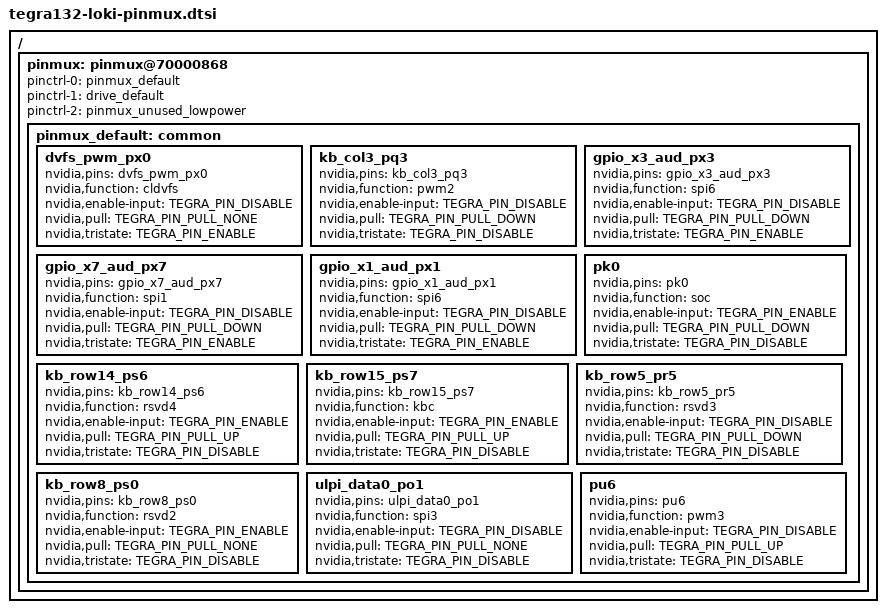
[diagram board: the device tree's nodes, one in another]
#include <dt-bindings/pinctrl/pinctrl-tegra.h>
#include <tegra124-platforms/tegra124-loki-pinmux.dtsi>

/ {
	pinmux: pinmux@70000868 {
		pinctrl-names = "default", "drive", "unused";
		pinctrl-0 = <&pinmux_default>;
		pinctrl-1 = <&drive_default>;
		pinctrl-2 = <&pinmux_unused_lowpower>;

		pinmux_default: common {
			dvfs_pwm_px0 {
				nvidia,pins = "dvfs_pwm_px0";
				nvidia,function = "cldvfs";
				nvidia,enable-input = <TEGRA_PIN_DISABLE>;
				nvidia,pull = <TEGRA_PIN_PULL_NONE>;
				nvidia,tristate = <TEGRA_PIN_ENABLE>;
			};

			kb_col3_pq3 {
				nvidia,pins = "kb_col3_pq3";
				nvidia,function = "pwm2";
				nvidia,enable-input = <TEGRA_PIN_DISABLE>;
				nvidia,pull = <TEGRA_PIN_PULL_DOWN>;
				nvidia,tristate = <TEGRA_PIN_DISABLE>;
			};

			gpio_x3_aud_px3 {
				nvidia,pins = "gpio_x3_aud_px3";
				nvidia,function = "spi6";
				nvidia,enable-input = <TEGRA_PIN_DISABLE>;
				nvidia,pull = <TEGRA_PIN_PULL_DOWN>;
				nvidia,tristate = <TEGRA_PIN_ENABLE>;
			};

			gpio_x7_aud_px7 {
				nvidia,pins = "gpio_x7_aud_px7";
				nvidia,function = "spi1";
				nvidia,enable-input = <TEGRA_PIN_DISABLE>;
				nvidia,pull = <TEGRA_PIN_PULL_DOWN>;
				nvidia,tristate = <TEGRA_PIN_ENABLE>;
			};

			gpio_x1_aud_px1 {
				nvidia,pins = "gpio_x1_aud_px1";
				nvidia,function = "spi6";
				nvidia,enable-input = <TEGRA_PIN_DISABLE>;
				nvidia,pull = <TEGRA_PIN_PULL_DOWN>;
				nvidia,tristate = <TEGRA_PIN_ENABLE>;
			};

			pk0 {
				nvidia,pins = "pk0";
				nvidia,function = "soc";
				nvidia,enable-input = <TEGRA_PIN_ENABLE>;
				nvidia,pull = <TEGRA_PIN_PULL_DOWN>;
				nvidia,tristate = <TEGRA_PIN_DISABLE>;
			};

			kb_row14_ps6 {
				nvidia,pins = "kb_row14_ps6";
				nvidia,function = "rsvd4";
				nvidia,enable-input = <TEGRA_PIN_ENABLE>;
				nvidia,pull = <TEGRA_PIN_PULL_UP>;
				nvidia,tristate = <TEGRA_PIN_DISABLE>;
			};

			kb_row15_ps7 {
				nvidia,pins = "kb_row15_ps7";
				nvidia,function = "kbc";
				nvidia,enable-input = <TEGRA_PIN_ENABLE>;
				nvidia,pull = <TEGRA_PIN_PULL_UP>;
				nvidia,tristate = <TEGRA_PIN_DISABLE>;
			};

			kb_row5_pr5 {
				nvidia,pins = "kb_row5_pr5";
				nvidia,function = "rsvd3";
				nvidia,enable-input = <TEGRA_PIN_DISABLE>;
				nvidia,pull = <TEGRA_PIN_PULL_DOWN>;
				nvidia,tristate = <TEGRA_PIN_DISABLE>;
			};

			kb_row8_ps0 {
				nvidia,pins = "kb_row8_ps0";
				nvidia,function = "rsvd2";
				nvidia,enable-input = <TEGRA_PIN_ENABLE>;
				nvidia,pull = <TEGRA_PIN_PULL_NONE>;
				nvidia,tristate = <TEGRA_PIN_DISABLE>;
			};

			ulpi_data0_po1 {
				nvidia,pins = "ulpi_data0_po1";
				nvidia,function = "spi3";
				nvidia,enable-input = <TEGRA_PIN_DISABLE>;
				nvidia,pull = <TEGRA_PIN_PULL_NONE>;
				nvidia,tristate = <TEGRA_PIN_DISABLE>;
			};

			pu6 {
				nvidia,pins = "pu6";
				nvidia,function = "pwm3";
				nvidia,enable-input = <TEGRA_PIN_DISABLE>;
				nvidia,pull = <TEGRA_PIN_PULL_UP>;
				nvidia,tristate = <TEGRA_PIN_DISABLE>;
			};
		};
	};
};
